VERSION ""

NS_ :

BS_:

BU_: BMS Third_Party_Device

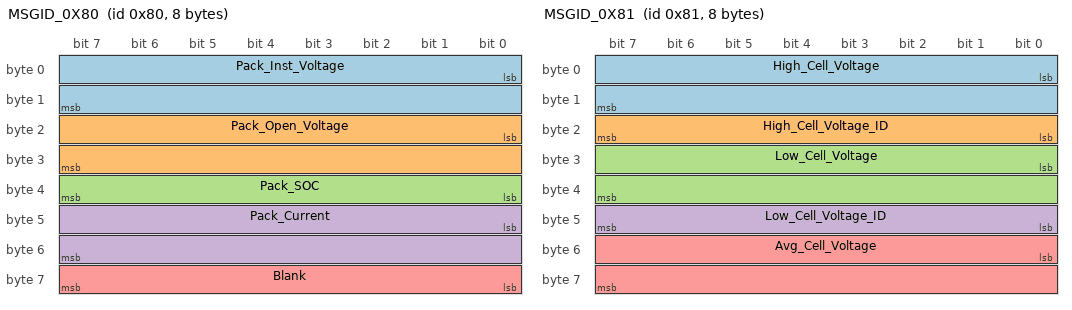
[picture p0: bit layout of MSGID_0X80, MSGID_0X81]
BO_ 128 MSGID_0X80: 8 BMS
 SG_ Pack_Inst_Voltage : 0|16@1+ (0.010000000000000002,0) [0|0] "Volts"  Third_Party_Device
 SG_ Pack_Open_Voltage : 16|16@1+ (0.010000000000000002,0) [0|0] "Volts"  Third_Party_Device
 SG_ Pack_SOC : 39|8@0+ (1.0,0) [0|0] "Percent"  Third_Party_Device
 SG_ Pack_Current : 40|16@1+ (0.1,0) [0|0] "Amps"  Third_Party_Device
 SG_ Blank : 63|8@0+ (1.0,1720) [0|0] ""  Third_Party_Device

BO_ 129 MSGID_0X81: 8 BMS
 SG_ High_Cell_Voltage : 0|16@1+ (1.0E-4,0) [0|0] "Volts"  Third_Party_Device
 SG_ High_Cell_Voltage_ID : 23|8@0+ (1.0,0) [0|0] "ID"  Third_Party_Device
 SG_ Low_Cell_Voltage : 24|16@1+ (1.0E-4,0) [0|0] "Volts"  Third_Party_Device
 SG_ Low_Cell_Voltage_ID : 47|8@0+ (1.0,0) [0|0] "ID"  Third_Party_Device
 SG_ Avg_Cell_Voltage : 48|16@1+ (1.0E-4,0) [0|0] "Volts"  Third_Party_Device

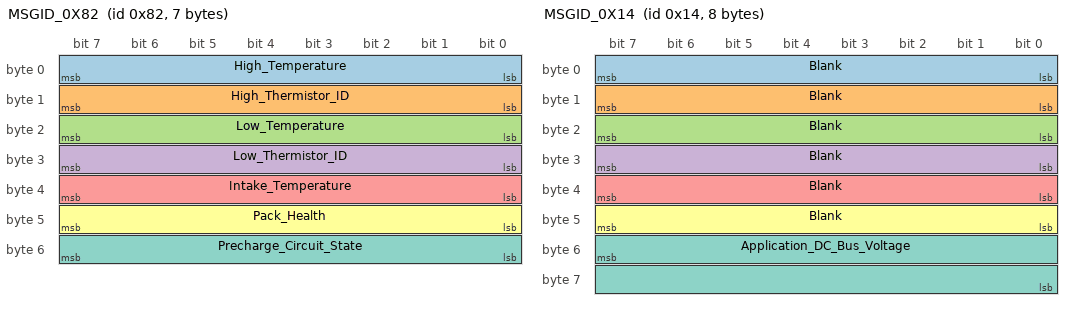
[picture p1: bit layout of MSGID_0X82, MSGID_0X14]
BO_ 130 MSGID_0X82: 7 BMS
 SG_ High_Temperature : 7|8@0+ (1.0,0) [0|0] "Celsius"  Third_Party_Device
 SG_ High_Thermistor_ID : 15|8@0+ (1.0,0) [0|0] "ID"  Third_Party_Device
 SG_ Low_Temperature : 23|8@0+ (1.0,0) [0|0] "Celsius"  Third_Party_Device
 SG_ Low_Thermistor_ID : 31|8@0+ (1.0,0) [0|0] "ID"  Third_Party_Device
 SG_ Intake_Temperature : 39|8@0+ (1.0,0) [0|0] "Celsius"  Third_Party_Device
 SG_ Pack_Health : 47|8@0+ (1.0,0) [0|0] "Percent"  Third_Party_Device
 SG_ Precharge_Circuit_State : 55|8@0+ (1.0,0) [0|0] ""  Third_Party_Device

BO_ 131 MSGID_0X83: 1 Third_Party_Device
 SG_ Precharge_Request : 7|8@0+ (1.0,0) [0|0] "ON/OFF"  BMS

BO_ 20 MSGID_0X14: 8 Third_Party_Device
 SG_ Blank : 7|8@0+ (1.0,0) [0|0] ""  BMS
 SG_ Blank : 15|8@0+ (1.0,0) [0|0] ""  BMS
 SG_ Blank : 23|8@0+ (100.0,0) [0|0] ""  BMS
 SG_ Blank : 31|8@0- (0.390625,2) [0|0] ""  BMS
 SG_ Blank : 39|8@0- (1.0,0) [0|0] ""  BMS
 SG_ Blank : 47|8@0+ (1.0,0) [0|0] ""  BMS
 SG_ Application_DC_Bus_Voltage : 55|16@0- (0.1,0) [0|0] "Volts"  BMS

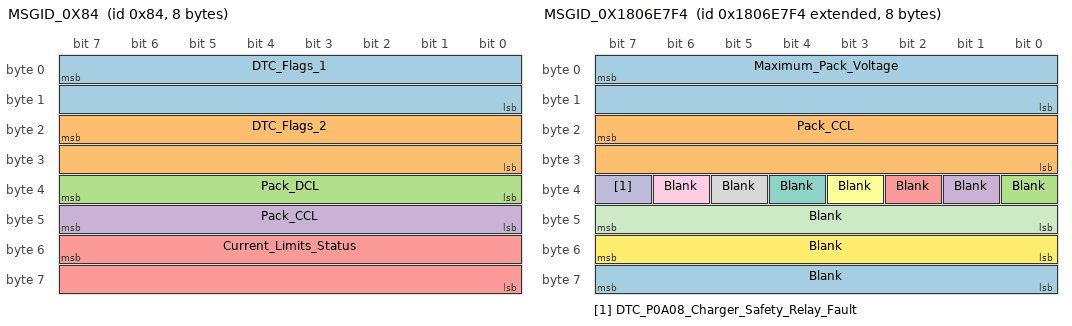
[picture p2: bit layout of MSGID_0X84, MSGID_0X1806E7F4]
BO_ 132 MSGID_0X84: 8 BMS
 SG_ DTC_Flags_1 : 7|16@0+ (1.0,0) [0|0] ""  Third_Party_Device
 SG_ DTC_Flags_2 : 23|16@0+ (1.0,0) [0|0] ""  Third_Party_Device
 SG_ Pack_DCL : 39|8@0+ (1.0,0) [0|0] "Amps"  Third_Party_Device
 SG_ Pack_CCL : 47|8@0+ (1.0,0) [0|0] "Amps"  Third_Party_Device
 SG_ Current_Limits_Status : 55|16@0+ (1.0,0) [0|0] ""  Third_Party_Device

BO_ 2550589428 MSGID_0X1806E7F4: 8 BMS
 SG_ Maximum_Pack_Voltage : 7|16@0+ (0.1,0) [0|0] "Volts"  Third_Party_Device
 SG_ Pack_CCL : 23|16@0+ (0.1,0) [0|0] "Amps"  Third_Party_Device
 SG_ Blank : 32|1@1+ (1.0,0) [0|1] ""  Third_Party_Device
 SG_ Blank : 33|1@1+ (1.0,0) [0|1] ""  Third_Party_Device
 SG_ Blank : 34|1@1+ (1.0,0) [0|1] ""  Third_Party_Device
 SG_ Blank : 35|1@1+ (1.0,0) [0|1] ""  Third_Party_Device
 SG_ Blank : 36|1@1+ (1.0,0) [0|1] ""  Third_Party_Device
 SG_ Blank : 37|1@1+ (1.0,0) [0|1] ""  Third_Party_Device
 SG_ Blank : 38|1@1+ (1.0,0) [0|1] ""  Third_Party_Device
 SG_ DTC_P0A08_Charger_Safety_Relay_Fault : 39|1@1+ (1.0,0) [0|1] ""  Third_Party_Device
 SG_ Blank : 47|8@0+ (0.1,0) [0|0] ""  Third_Party_Device
 SG_ Blank : 55|8@0+ (1.0,0) [0|0] ""  Third_Party_Device
 SG_ Blank : 63|8@0+ (1.0,0) [0|0] ""  Third_Party_Device

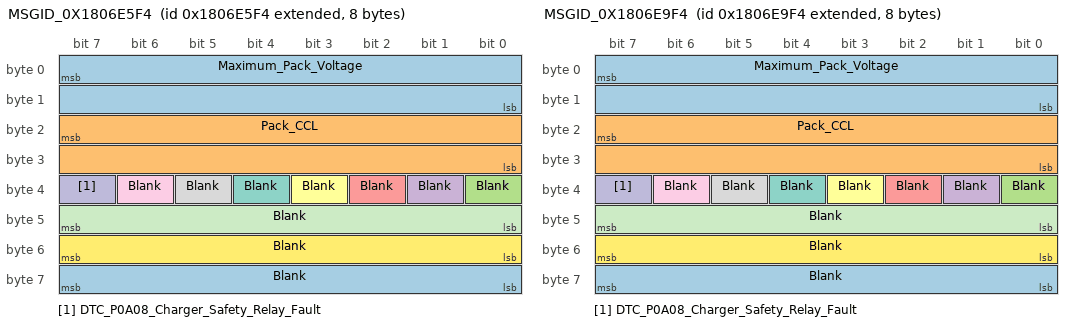
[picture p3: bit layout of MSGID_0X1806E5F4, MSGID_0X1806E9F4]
BO_ 2550588916 MSGID_0X1806E5F4: 8 BMS
 SG_ Maximum_Pack_Voltage : 7|16@0+ (0.1,0) [0|0] "Volts"  Third_Party_Device
 SG_ Pack_CCL : 23|16@0+ (0.1,0) [0|0] "Amps"  Third_Party_Device
 SG_ Blank : 32|1@1+ (1.0,0) [0|1] ""  Third_Party_Device
 SG_ Blank : 33|1@1+ (1.0,0) [0|1] ""  Third_Party_Device
 SG_ Blank : 34|1@1+ (1.0,0) [0|1] ""  Third_Party_Device
 SG_ Blank : 35|1@1+ (1.0,0) [0|1] ""  Third_Party_Device
 SG_ Blank : 36|1@1+ (1.0,0) [0|1] ""  Third_Party_Device
 SG_ Blank : 37|1@1+ (1.0,0) [0|1] ""  Third_Party_Device
 SG_ Blank : 38|1@1+ (1.0,0) [0|1] ""  Third_Party_Device
 SG_ DTC_P0A08_Charger_Safety_Relay_Fault : 39|1@1+ (1.0,0) [0|1] ""  Third_Party_Device
 SG_ Blank : 47|8@0+ (0.1,0) [0|0] ""  Third_Party_Device
 SG_ Blank : 55|8@0+ (1.0,0) [0|0] ""  Third_Party_Device
 SG_ Blank : 63|8@0+ (1.0,0) [0|0] ""  Third_Party_Device

BO_ 2550589940 MSGID_0X1806E9F4: 8 BMS
 SG_ Maximum_Pack_Voltage : 7|16@0+ (0.1,0) [0|0] "Volts"  Third_Party_Device
 SG_ Pack_CCL : 23|16@0+ (0.1,0) [0|0] "Amps"  Third_Party_Device
 SG_ Blank : 32|1@1+ (1.0,0) [0|1] ""  Third_Party_Device
 SG_ Blank : 33|1@1+ (1.0,0) [0|1] ""  Third_Party_Device
 SG_ Blank : 34|1@1+ (1.0,0) [0|1] ""  Third_Party_Device
 SG_ Blank : 35|1@1+ (1.0,0) [0|1] ""  Third_Party_Device
 SG_ Blank : 36|1@1+ (1.0,0) [0|1] ""  Third_Party_Device
 SG_ Blank : 37|1@1+ (1.0,0) [0|1] ""  Third_Party_Device
 SG_ Blank : 38|1@1+ (1.0,0) [0|1] ""  Third_Party_Device
 SG_ DTC_P0A08_Charger_Safety_Relay_Fault : 39|1@1+ (1.0,0) [0|1] ""  Third_Party_Device
 SG_ Blank : 47|8@0+ (1.0,0) [0|0] ""  Third_Party_Device
 SG_ Blank : 55|8@0+ (1.0,0) [0|0] ""  Third_Party_Device
 SG_ Blank : 63|8@0+ (1.0,0) [0|0] ""  Third_Party_Device

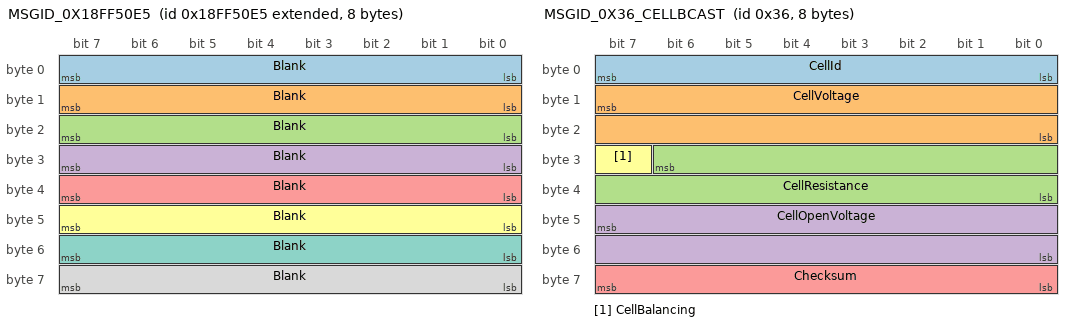
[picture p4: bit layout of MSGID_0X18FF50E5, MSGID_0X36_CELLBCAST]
BO_ 2566869221 MSGID_0X18FF50E5: 8 Third_Party_Device
 SG_ Blank : 7|8@0+ (1.0,0) [0|0] ""  BMS
 SG_ Blank : 15|8@0+ (1.0,0) [0|0] ""  BMS
 SG_ Blank : 23|8@0+ (1.0,0) [0|0] ""  BMS
 SG_ Blank : 31|8@0+ (1.0,0) [0|0] ""  BMS
 SG_ Blank : 39|8@0+ (1.0,0) [0|0] ""  BMS
 SG_ Blank : 47|8@0+ (1.0,0) [0|0] ""  BMS
 SG_ Blank : 55|8@0+ (1.0,0) [0|0] ""  BMS
 SG_ Blank : 63|8@0+ (1.0,0) [0|0] ""  BMS

BO_ 54 MSGID_0X36_CELLBCAST: 8 BMS
 SG_ CellId : 7|8@0+ (1,0) [0|0] "#" Third_Party_Device
 SG_ CellVoltage : 15|16@0+ (0.0001,0) [0|0] "Volts" Third_Party_Device
 SG_ CellResistance : 30|15@0+ (0.01,0) [0|0] "mOhms" Third_Party_Device
 SG_ CellOpenVoltage : 47|16@0+ (0.0001,0) [0|0] "Volts" Third_Party_Device
 SG_ Checksum : 63|8@0+ (1,0) [0|0] "" Third_Party_Device
 SG_ CellBalancing : 31|1@1+ (1,0) [0|0] "" Third_Party_Device
CM_ BO_ 128 "This ID Transmits at 8 ms.";
CM_ BO_ 129 "This ID Transmits at 24 ms.";
CM_ BO_ 130 "This ID Transmits at 104 ms.";
CM_ BO_ 132 "This ID Transmits at 24 ms.";
CM_ BO_ 2550589428 "This ID Transmits at 808 ms.";
CM_ BO_ 2550588916 "This ID Transmits at 808 ms.";
CM_ BO_ 2550589940 "This ID Transmits at 808 ms.";
CM_ BO_ 54 "This ID Transmits at 4 ms.";
CM_ SG_ 54 Checksum "Value = (0x36 + 8 + byte0 + byte1 + ... + byte6) & 0xFF";
